# ADSP-SC83xW_HPC register map
Vendor: Analog Devices; Series: ADSP-SC83xW_HPC; File version: 3.0.3.517
CPU: 
Registers are 32-bit, read-write, reset 0x0 unless marked. A register's access mark holds for its fields unless they carry their own. Offsets are from the block's base; [hi:lo] are bit positions; {n}, {i} and the like mark numbered series.

## PADS0 — Pads Controller
Base 0x31004600
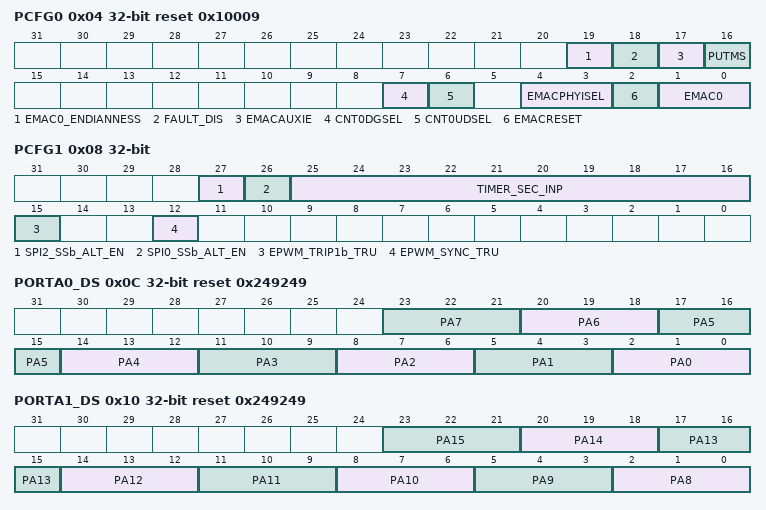
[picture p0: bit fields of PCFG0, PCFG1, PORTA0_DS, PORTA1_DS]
0x04 PCFG0 reset 0x10009 — Peripheral PAD Configuration0 Register
  [19] EMAC0_ENDIANNESS — EMAC0 DMA Transfer Format
  [18] FAULT_DIS — FAULT does not exist
  [17] EMACAUXIE — Input enable control for ETH_PTPAUX_MCG_IN and ETH_PTPCLKIN pins
  [16] PUTMS — Pull-Up Enable for TMS/SWDIO (debug port)
  [7] CNT0DGSEL — CNT0 Down Input Select
  [6] CNT0UDSEL — CNT0 Up Input Select
  [4:3] EMACPHYISEL — Select PHY Interface RGMII/RMII/MII
    0=EMACPHY_MII (MII Interface); 1=EMACPHY_RGMII (RGMII Interface); 2=EMACPHY_RMII (RMII Interface)
  [2] EMACRESET — Reset Enable for RGMII
  [1:0] EMAC0 — PTP Clock Source 0
    0=EMAC0_RMII_CLK (REFCLK (MII or RMII) or CLKO7 (RGMII)); 1=EMAC0_SCLK1 (SCLK0); 2=EMAC0_EXT_CLK (External PTP clock); 3=EMAC0_SCLK3 (SCLK0)
0x08 PCFG1 — Peripheral Configuration1 Register
  [27] SPI2_SSb_ALT_EN range 0x00000000..0x00000001 — Alternate Pin input enable for SPI2_SSb. 0: PA[5]. 1: PE[2]
  [26] SPI0_SSb_ALT_EN range 0x00000000..0x00000001 — Alternate Pin input enable for SPI0_SSb. 0: PA[9]. 1: PE[15]
  [25:16] TIMER_SEC_INP — Secondary Input Select
    1=TIMER0_CLK; 2=TIMER0_ACI0; 4=TIMER0_ACI1; 8=TIMER0_ACI2; 16=TIMER0_ACI3; 32=TIMER0_ACI4; 64=TIMER0_ACLK1
  [15] EPWM_TRIP1b_TRU range 0x00000000..0x00000001 — PWM TRIP1b input enable
  [12] EPWM_SYNC_TRU range 0x00000000..0x00000001 — PWM SYNC Enable
0x0C PORTA0_DS reset 0x249249 — PORTA 0 to 7 pins DS control
  [3n+2:3n] PA{n} (n=0..7) — DS control for PA{n} IO
0x10 PORTA1_DS reset 0x249249 — PORTA 8 - 15 pins DS control
  [3n-22:3n-24] PA{n} (n=8..15) — DS control for PA{n} IO
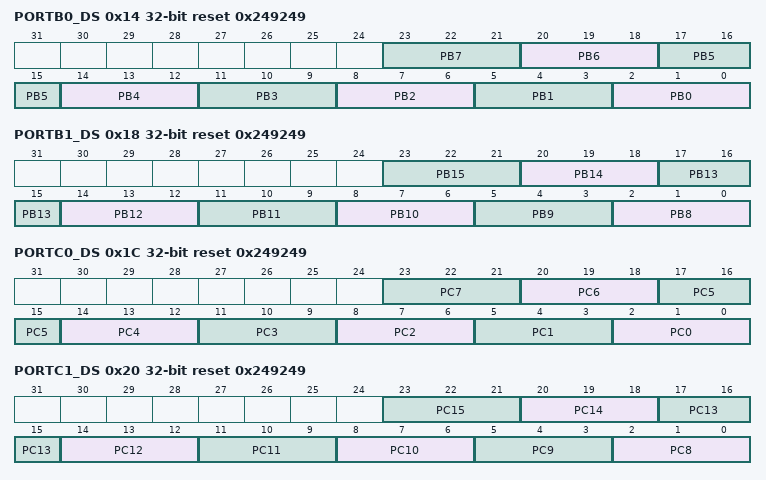
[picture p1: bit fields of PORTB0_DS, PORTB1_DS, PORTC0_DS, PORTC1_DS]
0x14 PORTB0_DS reset 0x249249 — PORTB 0 to 7 pins DS control
  [3n+2:3n] PB{n} (n=0..7) — DS control for PB{n} IO
0x18 PORTB1_DS reset 0x249249 — PORTB 8 - 15 pins DS control
  [3n-22:3n-24] PB{n} (n=8..15) — DS control for PB{n} IO
0x1C PORTC0_DS reset 0x249249 — PORTC 0 to 7 pins DS control
  [3n+2:3n] PC{n} (n=0..7) — DS control for PC{n} IO
0x20 PORTC1_DS reset 0x249249 — PORTC 8 - 15 pins DS control
  [3n-22:3n-24] PC{n} range 0x00000000..0x00000007 (n=8..15) — DS control for PC{n} IO
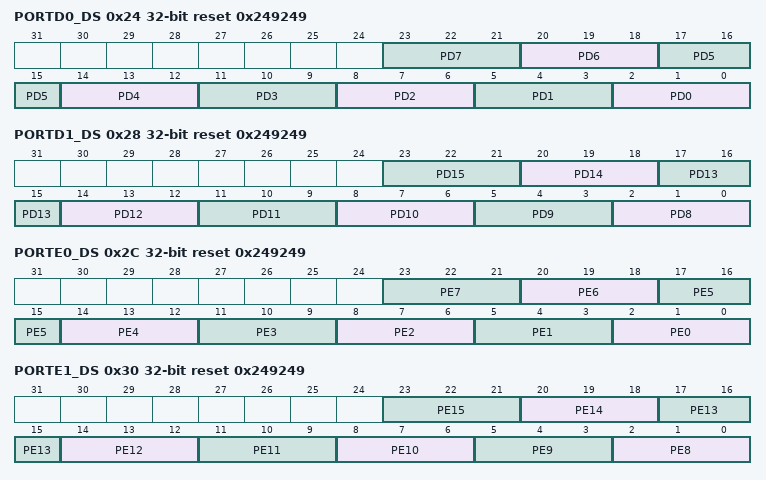
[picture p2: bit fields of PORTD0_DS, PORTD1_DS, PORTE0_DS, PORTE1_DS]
0x24 PORTD0_DS reset 0x249249 — PORTD 0 to 7 pins DS control
  [3n+2:3n] PD{n} range 0x00000000..0x00000007 (n=0..7) — DS control for PD{n} IO
0x28 PORTD1_DS reset 0x249249 — PORTD 8 to 15 pins DS control
  [3n-22:3n-24] PD{n} range 0x00000000..0x00000007 (n=8..15) — DS control for PD{n} IO
0x2C PORTE0_DS reset 0x249249 — PORTE 0 to 7 pins DS control
  [3n+2:3n] PE{n} range 0x00000000..0x00000007 (n=0..7) — DS control for PE{n} IO
0x30 PORTE1_DS reset 0x249249 — PORTE 8 to 15 pins DS control
  [3n-22:3n-24] PE{n} range 0x00000000..0x00000007 (n=8..15) — DS control for PE{n} IO
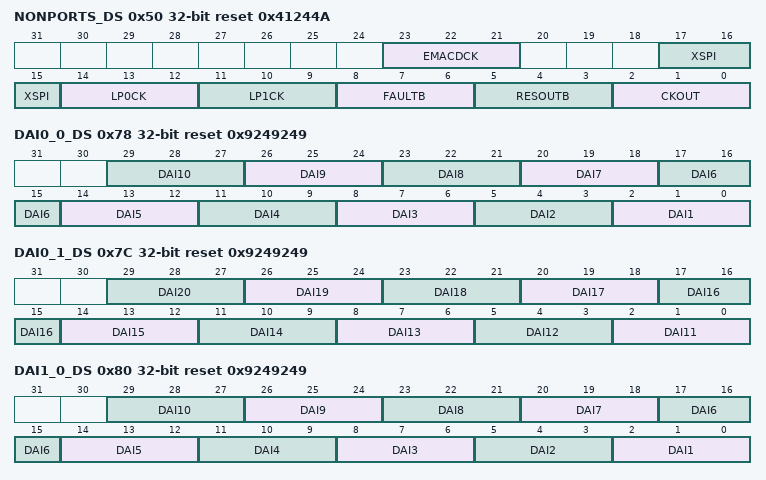
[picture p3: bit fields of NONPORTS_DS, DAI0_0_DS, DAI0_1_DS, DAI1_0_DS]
0x50 NONPORTS_DS reset 0x41244A — Non-GPIO Drive Strength Register
  [23:21] EMACDCK — EMAC Drive Strength Control
  [17:15] XSPI — XSPI pins DS control
  [14:12] LP0CK — LP0 Clock Drive Strength Control
  [11:9] LP1CK — LP1 Clock Drive Strength Control
  [8:6] FAULTB — FAULTB DS control
  [5:3] RESOUTB — RESOUTB DS control
  [2:0] CKOUT — CLKOUT DS control
0x78 DAI0_0_DS reset 0x9249249 — DAI0 1 to 10 pins DS control
  [3n-1:3n-3] DAI{n} (n=1..10) — DS control for DAI{n} IO
0x7C DAI0_1_DS reset 0x9249249 — DAI0 11 to 20 pins DS control
  [3n-31:3n-33] DAI{n} (n=11..20) — DS control for DAI{n} IO
0x80 DAI1_0_DS reset 0x9249249 — DAI1 1 to 10 pins DS control
  [3n-1:3n-3] DAI{n} (n=1..10) — DS control for DAI{n} IO
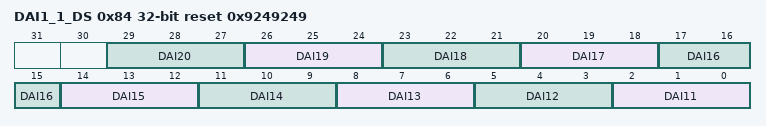
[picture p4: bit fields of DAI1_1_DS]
0x84 DAI1_1_DS reset 0x9249249 — DAI1 11 to 20 pins DS control
  [3n-31:3n-33] DAI{n} (n=11..20) — DS control for DAI{n} IO
0x90 DAI0_IE — DAI0 Port Input Enable Control Register
  [19:0] VALUE range 0x00000000..0x000FFFFF — DAI0 Input Enable Control
0x94 DAI1_IE — DAI1 Port Input Enable Control Register
  [19:0] VALUE range 0x00000000..0x000FFFFF — DAI1 Input Enable Control
0x98 PORTA_PUE — PORT[n] Pull-Up Enable
  [15:0] PUE range 0x00000000..0x0000FFFF — Pull-Up Enable
0x9C PORTB_PUE — PORT[n] Pull-Up Enable
  [15:0] PUE range 0x00000000..0x0000FFFF — Pull-Up Enable
0xA0 PORTC_PUE — PORT[n] Pull-Up Enable
  [15:0] PUE range 0x00000000..0x0000FFFF — Pull-Up Enable
0xA4 PORTD_PUE — PORT[n] Pull-Up Enable
  [15:0] PUE range 0x00000000..0x0000FFFF — Pull-Up Enable
0xA8 PORTE_PUE — PORT[n] Pull-Up Enable
  [15:0] PUE range 0x00000000..0x0000FFFF — Pull-Up Enable
0xBC DAI0_PUE — DAI[n] Pull-Up Enable
  [19:0] PUE range 0x00000000..0x000FFFFF — Pull-Up Enable
0xC0 DAI1_PUE — DAI[n] Pull-Up Enable
  [19:0] PUE range 0x00000000..0x000FFFFF — Pull-Up Enable
0xC4 PORTA_PDE — PORT[n] Pull-Down Enable
  [15:0] PDE range 0x00000000..0x0000FFFF — Pull-Down Enable
0xC8 PORTB_PDE — PORT[n] Pull-Down Enable
  [15:0] PDE range 0x00000000..0x0000FFFF — Pull-Down Enable
0xCC PORTC_PDE — PORT[n] Pull-Down Enable
  [15:0] PDE range 0x00000000..0x0000FFFF — Pull-Down Enable
0xD0 PORTD_PDE — PORT[n] Pull-Down Enable
  [15:0] PDE range 0x00000000..0x0000FFFF — Pull-Down Enable
0xD4 PORTE_PDE — PORT[n] Pull-Down Enable
  [15:0] PDE range 0x00000000..0x0000FFFF — Pull-Down Enable
0xFC DAI0_PDE — DAI[n] Pull-Down Enable
  [19:0] PDE range 0x00000000..0x000FFFFF — Pull-Down Enable
0x100 DAI1_PDE — DAI[n] Pull-Down Enable
  [19:0] PDE range 0x00000000..0x000FFFFF — Pull-Down Enable
